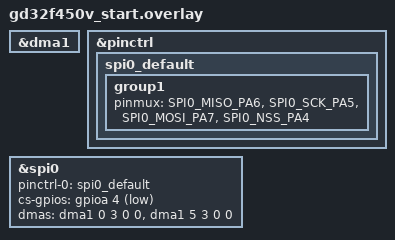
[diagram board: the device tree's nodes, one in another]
/*
 * SPDX-License-Identifier: Apache-2.0
 *
 * Copyright (c) 2022 TOKITA Hiroshi <tokita.hiroshi@gmail.com>
 */

#include <zephyr/dt-bindings/dma/gd32_dma.h>

&dma1 {
	status = "okay";
};

&pinctrl {
	spi0_default: spi0_default {
		group1 {
			pinmux = <SPI0_MISO_PA6>, <SPI0_SCK_PA5>,
				 <SPI0_MOSI_PA7>, <SPI0_NSS_PA4>;
		};
	};
};

spi_loopback: &spi0 {
	status = "okay";
	pinctrl-0 = <&spi0_default>;
	pinctrl-names = "default";

	cs-gpios = <&gpioa 4 GPIO_ACTIVE_LOW>;

	dmas = <&dma1 0 3 0 0>, <&dma1 5 3 0 0>;
	dma-names = "rx", "tx";
};

#include "../spi-loopback.dtsi"
